AUTOSAR XML (schema 4-2-2)
package /ComponentTypes
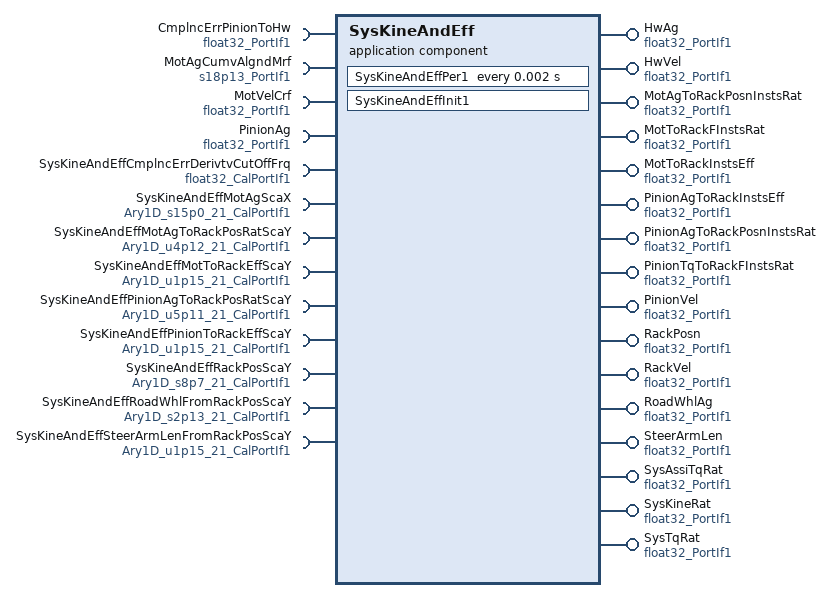
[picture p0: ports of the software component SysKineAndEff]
  application sw component type SysKineAndEff  # In a variable ratio system the kinematic ratio and mechanical efficiency of the input and motortorque can change as the rack moves. This componentcalculates the Efficiencies and Ratios based onthe Rack movement.
    16 x provide port, all with provided-interface=float32_PortIf1:
      HwAg: nonqueued-sender-com-spec{data-element=Val, init-value=0}  # Handwheel Position
      HwVel: nonqueued-sender-com-spec{data-element=Val, init-value=0}  # Handwheel velocity derived from pinion velocity plus tbar velocity
      MotAgToRackPosnInstsRat: nonqueued-sender-com-spec{data-element=Val, init-value=0.01}  # Instantaneous motor angle to rack position ratio, ballscrewlead and belt ratio for a REPS, worm gear to worm ratio for CEPS
      MotToRackFInstsRat: nonqueued-sender-com-spec{data-element=Val, init-value=3000}  # Instantaneous motor torque to rack force ratio
      MotToRackInstsEff: nonqueued-sender-com-spec{data-element=Val, init-value=0.86}  # Instantaneous motor torque to rack force efficiency
      PinionAgToRackInstsEff: nonqueued-sender-com-spec{data-element=Val, init-value=0.92}  # Instantaneous pinion torque to rack force efficiency
      PinionAgToRackPosnInstsRat: nonqueued-sender-com-spec{data-element=Val, init-value=10}  # Instantaneous handwheel to rack position ratio defined by the c-factor profile
      PinionTqToRackFInstsRat: nonqueued-sender-com-spec{data-element=Val, init-value=200}  # Instantaneous conversion factor for rack force from hand wheel torque
      PinionVel: nonqueued-sender-com-spec{data-element=Val, init-value=0}  # Pinion velocity derived from rack velocity
      RackPosn: nonqueued-sender-com-spec{data-element=Val, init-value=0}  # Rack position derived from motor angle
      RackVel: nonqueued-sender-com-spec{data-element=Val, init-value=0}  # Rack velocity derived from motor velocity
      RoadWhlAg: nonqueued-sender-com-spec{data-element=Val, init-value=0}  # Road wheel angle as defined by the bicycle model, derived from rack position
      SteerArmLen: nonqueued-sender-com-spec{data-element=Val, init-value=200}  # Instantaneous steering arm length, used by the bicyle model to estimate rack force
      SysAssiTqRat: nonqueued-sender-com-spec{data-element=Val, init-value=26}  # Instantaneous handwheel to motor torque ratio, from the reference frame of what torque would the motor have to apply to be the equivalent of the driver applying torque, usedfor calculating motor assist curves in handwheel coordinates
      SysKineRat: nonqueued-sender-com-spec{data-element=Val, init-value=28}  # Instantaneous handwheel to motor position ratio
      SysTqRat: nonqueued-sender-com-spec{data-element=Val, init-value=26}  # Instantaneous handwheel to motor torque ratio, from the reference frame of what would the reaction handwheel torque be when applyingtorque with the motor
    13 x require port:
      CmplncErrPinionToHw: nonqueued-receiver-com-spec{data-element=Val, filter=data-filter-type=ALWAYS, init-value=0}, required-interface=float32_PortIf1  # Lost motion between Pinion and Handwheel
      MotAgCumvAlgndMrf: nonqueued-receiver-com-spec{data-element=Val, filter=data-filter-type=ALWAYS, init-value=0}, required-interface=s18p13_PortIf1  # Absolute motor angle that is an accurate indication of center when HwAuth is 1
      MotVelCrf: nonqueued-receiver-com-spec{data-element=Val, filter=data-filter-type=ALWAYS, init-value=0}, required-interface=float32_PortIf1  # Motor Velocity beased on assist mech polarity
      PinionAg: nonqueued-receiver-com-spec{data-element=Val, filter=data-filter-type=ALWAYS, init-value=0}, required-interface=float32_PortIf1  # Angle measured at the pinion angle sensor
      SysKineAndEffCmplncErrDerivtvCutOffFrq: parameter-require-com-spec{init-value=25, parameter=Val}, required-interface=float32_CalPortIf1  # Range for Compliance Error Derivative Cut Off Frequency
      SysKineAndEffMotAgScaX: parameter-require-com-spec{init-value=[-19165, -17140, -15133, -13161, -11222, -9315, -7437, -5574, -3716, -1858, 0, 1858, 3715, 5573, 7431, 9293, 11172, 13078, 15017, 16989, 18995], parameter=Ary1D}, required-interface=Ary1D_s15p0_21_CalPortIf1  # X table for looking up rack position based on motor angle
      SysKineAndEffMotAgToRackPosRatScaY: parameter-require-com-spec{init-value=[1233, 1237, 1241, 1245, 1249, 1253, 1257, 1262, 1262, 1262, 1262, 1262, 1262, 1262, 1257, 1253, 1249, 1245, 1241, 1237, 1233], parameter=Ary1D}, required-interface=Ary1D_u4p12_21_CalPortIf1  # Y table for looking up motor angle to rack position ratio based on rack position
      SysKineAndEffMotToRackEffScaY: parameter-require-com-spec{init-value=[27853, 27918, 27984, 28049, 28115, 28180, 28180, 28180, 28180, 28180, 28180, 28180, 28180, 28180, 28180, 28180, 28115, 28049, 27984, 27918, 27853], parameter=Ary1D}, required-interface=Ary1D_u1p15_21_CalPortIf1  # Y table for looking up motor to rack efficiency based on rack position
      SysKineAndEffPinionAgToRackPosRatScaY: parameter-require-com-spec{init-value=[17592, 17592, 17592, 17285, 16589, 15770, 14930, 14213, 13926, 13681, 13681, 13681, 13926, 14213, 14930, 15770, 16589, 17285, 17592, 17592, 17592], parameter=Ary1D}, required-interface=Ary1D_u5p11_21_CalPortIf1  # Y table or looking up pinion angle to rack position ratio based on rack position
      SysKineAndEffPinionToRackEffScaY: parameter-require-com-spec{init-value=[29491, 29655, 29819, 29983, 30147, 30147, 30147, 30147, 30147, 30147, 30147, 30147, 30147, 30147, 30147, 30147, 30147, 29983, 29819, 29655, 29491], parameter=Ary1D}, required-interface=Ary1D_u1p15_21_CalPortIf1  # Y table for looking up pinion to rack efficiency based on rack position
      SysKineAndEffRackPosScaY: parameter-require-com-spec{init-value=[-12800, -11520, -10240, -8960, -7680, -6400, -5120, -3840, -2560, -1280, 0, 1280, 2560, 3840, 5120, 6400, 7680, 8960, 10240, 11520, 12800], parameter=Ary1D}, required-interface=Ary1D_s8p7_21_CalPortIf1  # Y table to lookup rack position based on motor position, and the x table for mulitple other lookup tables
      SysKineAndEffRoadWhlFromRackPosScaY: parameter-require-com-spec{init-value=[-5939, -5300, -4678, -4063, -3465, -2867, -2277, -1704, -1139, -565, 0, 565, 1139, 1704, 2277, 2867, 3465, 4063, 4678, 5300, 5939], parameter=Ary1D}, required-interface=Ary1D_s2p13_21_CalPortIf1  # Y table for looking up road wheel angle based on rack position
      SysKineAndEffSteerArmLenFromRackPosScaY: parameter-require-com-spec{init-value=[4522, 4555, 4588, 4620, 4653, 4686, 4719, 4719, 4719, 4719, 4719, 4719, 4719, 4719, 4719, 4686, 4653, 4620, 4588, 4555, 4522], parameter=Ary1D}, required-interface=Ary1D_u1p15_21_CalPortIf1  # Y table for looking up steer arm length based on rack position
    behavior SysKineAndEff_InternalBehavior
      ar-typed-per-instance-memorys:
        data CmplncErrDerivtvPrev: sw-calibration-access=READ-ONLY, type=float32  # Previous value of Compliance Error Derivative
        data CmplncErrPinionToHwPrev: sw-calibration-access=READ-ONLY, type=float32  # Previous value of Compliance Error Pinion To Handwheel
      init event SysKineAndEff_InitEvent: start-on-event=SysKineAndEffInit1
      timing event TMT_SysKineAndEffPer1: start-on-event=SysKineAndEffPer1, period=0.002
      port-api-options:
        enable-take-address=false, error-handling=NO-TRANSFORMER-ERROR-HANDLING, indirect-api=false, port=HwVel
        enable-take-address=false, error-handling=NO-TRANSFORMER-ERROR-HANDLING, indirect-api=false, port=MotAgToRackPosnInstsRat
        enable-take-address=false, error-handling=NO-TRANSFORMER-ERROR-HANDLING, indirect-api=false, port=MotToRackInstsEff
        enable-take-address=false, error-handling=NO-TRANSFORMER-ERROR-HANDLING, indirect-api=false, port=MotVelCrf
        enable-take-address=false, error-handling=NO-TRANSFORMER-ERROR-HANDLING, indirect-api=false, port=PinionAg
        enable-take-address=false, error-handling=NO-TRANSFORMER-ERROR-HANDLING, indirect-api=false, port=PinionAgToRackInstsEff
        enable-take-address=false, error-handling=NO-TRANSFORMER-ERROR-HANDLING, indirect-api=false, port=PinionTqToRackFInstsRat
        enable-take-address=false, error-handling=NO-TRANSFORMER-ERROR-HANDLING, indirect-api=false, port=RackPosn
        enable-take-address=false, error-handling=NO-TRANSFORMER-ERROR-HANDLING, indirect-api=false, port=RackVel
        enable-take-address=false, error-handling=NO-TRANSFORMER-ERROR-HANDLING, indirect-api=false, port=RoadWhlAg
        enable-take-address=false, error-handling=NO-TRANSFORMER-ERROR-HANDLING, indirect-api=false, port=SteerArmLen
        enable-take-address=false, error-handling=NO-TRANSFORMER-ERROR-HANDLING, indirect-api=false, port=SysAssiTqRat
        enable-take-address=false, error-handling=NO-TRANSFORMER-ERROR-HANDLING, indirect-api=false, port=SysKineAndEffCmplncErrDerivtvCutOffFrq
        enable-take-address=false, error-handling=NO-TRANSFORMER-ERROR-HANDLING, indirect-api=false, port=SysKineAndEffMotAgScaX
        enable-take-address=false, error-handling=NO-TRANSFORMER-ERROR-HANDLING, indirect-api=false, port=SysKineAndEffMotToRackEffScaY
        enable-take-address=false, error-handling=NO-TRANSFORMER-ERROR-HANDLING, indirect-api=false, port=SysKineAndEffPinionToRackEffScaY
        enable-take-address=false, error-handling=NO-TRANSFORMER-ERROR-HANDLING, indirect-api=false, port=SysKineAndEffRoadWhlFromRackPosScaY
        enable-take-address=false, error-handling=NO-TRANSFORMER-ERROR-HANDLING, indirect-api=false, port=SysKineAndEffSteerArmLenFromRackPosScaY
        enable-take-address=false, error-handling=NO-TRANSFORMER-ERROR-HANDLING, indirect-api=false, port=SysKineRat
        enable-take-address=false, error-handling=NO-TRANSFORMER-ERROR-HANDLING, indirect-api=false, port=SysTqRat
      runnable SysKineAndEffInit1  # Initialization Runnable
      runnable SysKineAndEffPer1  # Periodic Runnable at 2ms
        data-receive-point-by-arguments:
          4 x access:
            REC_CmplncErrPinionToHw_Val: accessed-variable=CmplncErrPinionToHw.Val
            REC_MotAgCumvAlgndMrf_Val: accessed-variable=MotAgCumvAlgndMrf.Val
            REC_MotVelCrf_Val: accessed-variable=MotVelCrf.Val
            REC_PinionAg_Val: accessed-variable=PinionAg.Val
        data-send-points:
          16 x access:
            SEND_HwAg_Val: accessed-variable=HwAg.Val
            SEND_HwVel_Val: accessed-variable=HwVel.Val
            SEND_MotAgToRackPosnInstsRat_Val: accessed-variable=MotAgToRackPosnInstsRat.Val
            SEND_MotToRackFInstsRat_Val: accessed-variable=MotToRackFInstsRat.Val
            SEND_MotToRackInstsEff_Val: accessed-variable=MotToRackInstsEff.Val
            SEND_PinionAgToRackInstsEff_Val: accessed-variable=PinionAgToRackInstsEff.Val
            SEND_PinionAgToRackPosnInstsRat_Val: accessed-variable=PinionAgToRackPosnInstsRat.Val
            SEND_PinionTqToRackFInstsRat_Val: accessed-variable=PinionTqToRackFInstsRat.Val
            SEND_PinionVel_Val: accessed-variable=PinionVel.Val
            SEND_RackPosn_Val: accessed-variable=RackPosn.Val
            SEND_RackVel_Val: accessed-variable=RackVel.Val
            SEND_RoadWhlAg_Val: accessed-variable=RoadWhlAg.Val
            SEND_SteerArmLen_Val: accessed-variable=SteerArmLen.Val
            SEND_SysAssiTqRat_Val: accessed-variable=SysAssiTqRat.Val
            SEND_SysKineRat_Val: accessed-variable=SysKineRat.Val
            SEND_SysTqRat_Val: accessed-variable=SysTqRat.Val
  swc implementation SysKineAndEff_Implementation: behavior=SysKineAndEff_InternalBehavior
    code-descriptors:
      code Default: artifact-descriptors=autosar-engineering-object={short-label=Default, category=SWSRC}
